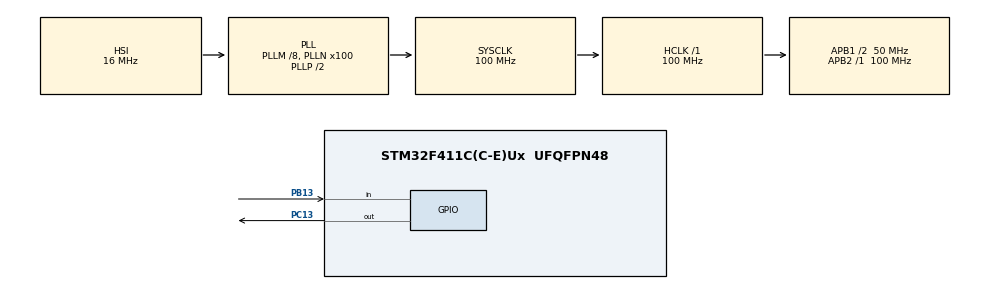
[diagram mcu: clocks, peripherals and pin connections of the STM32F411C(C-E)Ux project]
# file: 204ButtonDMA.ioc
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Dma.Request0=TIM2_CH3/UP
Dma.TIM2_CH3/UP.0.Direction=DMA_PERIPH_TO_MEMORY
Dma.TIM2_CH3/UP.0.FIFOMode=DMA_FIFOMODE_DISABLE
Dma.TIM2_CH3/UP.0.Instance=DMA1_Stream1
Dma.TIM2_CH3/UP.0.MemDataAlignment=DMA_MDATAALIGN_HALFWORD
Dma.TIM2_CH3/UP.0.MemInc=DMA_MINC_ENABLE
Dma.TIM2_CH3/UP.0.Mode=DMA_CIRCULAR
Dma.TIM2_CH3/UP.0.PeriphDataAlignment=DMA_PDATAALIGN_HALFWORD
Dma.TIM2_CH3/UP.0.PeriphInc=DMA_PINC_DISABLE
Dma.TIM2_CH3/UP.0.Priority=DMA_PRIORITY_LOW
Mcu.Family=STM32F4
Mcu.Name=STM32F411C(C-E)Ux
Mcu.Package=UFQFPN48
NVIC.DMA1_Stream1_IRQn=true\:0\:0\:false\:false\:true\:false\:true\:true
NVIC.PriorityGroup=NVIC_PRIORITYGROUP_4
PA13.Mode=Serial_Wire
PA13.Signal=SYS_JTMS-SWDIO
PA14.Mode=Serial_Wire
PA14.Signal=SYS_JTCK-SWCLK
PB13.GPIO_PuPd=GPIO_PULLUP
PB13.Signal=GPIO_Input
PC13-ANTI_TAMP.GPIO_PuPd=GPIO_NOPULL
PC13-ANTI_TAMP.Signal=GPIO_Output
ProjectManager.HeapSize=0x200
ProjectManager.StackSize=0x400
ProjectManager.TargetToolchain=STM32CubeIDE
RCC.48MHZClocksFreq_Value=50000000
RCC.AHBFreq_Value=100000000
RCC.APB1CLKDivider=RCC_HCLK_DIV2
RCC.APB1Freq_Value=50000000
RCC.APB1TimFreq_Value=100000000
RCC.APB2Freq_Value=100000000
RCC.APB2TimFreq_Value=100000000
RCC.CortexFreq_Value=100000000
RCC.HCLKFreq_Value=100000000
RCC.HSE_VALUE=25000000
RCC.HSI_VALUE=16000000
RCC.LSE_VALUE=32768
RCC.PLLM=8
RCC.PLLN=100
RCC.SYSCLKFreq_VALUE=100000000
RCC.SYSCLKSource=RCC_SYSCLKSOURCE_PLLCLK
RCC.VCOOutputFreq_Value=200000000
TIM2.Period=100-1
TIM2.Prescaler=1000-1
TIM2.TIM_MasterOutputTrigger=TIM_TRGO_UPDATE
VP_TIM2_VS_ClockSourceINT.Mode=Internal
board=custom

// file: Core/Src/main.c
/* USER CODE BEGIN Header */
/**
  ******************************************************************************
  * @file           : main.c
  * @brief          : Main program body
  ******************************************************************************
  * @attention
  *
  * Copyright (c) 2025 STMicroelectronics.
  * All rights reserved.
  *
  * This software is licensed under terms that can be found in the LICENSE file
  * in the root directory of this software component.
  * If no LICENSE file comes with this software, it is provided AS-IS.
  *
  ******************************************************************************
  */

//La Fórmula Clave
//La relación entre estos parámetros y el tiempo deseado es la siguiente:
//
//Frecuencia_Deseada = Frecuencia_Reloj_Entrada / ((Prescaler + 1) * (Counter_Period + 1))
//
//O, si quieres calcular el Tiempo_Período (el inverso de la frecuencia):
//
//Tiempo_Período = ((Prescaler + 1) * (Counter_Period + 1)) / Frecuencia_Reloj_Entrada

#include <stdio.h>
/* USER CODE END Header */
#include "main.h"

TIM_HandleTypeDef htim2;
DMA_HandleTypeDef hdma_tim2_ch3_up;

void SystemClock_Config(void);
static void MX_GPIO_Init(void);
static void MX_DMA_Init(void);
static void MX_TIM2_Init(void);

/* USER CODE BEGIN 0 */

#define SAMPLES  64
uint16_t buffer[SAMPLES]; // Guarda el estado completo de GPIOB cada 1 ms
/* USER CODE END 0 */

int main(void)
{

  /* MCU Configuration--------------------------------------------------------*/

  /* Reset of all peripherals, Initializes the Flash interface and the Systick. */
  HAL_Init();

  /* Configure the system clock */
  SystemClock_Config();

  /* Initialize all configured peripherals */
  MX_GPIO_Init();
  MX_DMA_Init();
  MX_TIM2_Init();
  /* USER CODE BEGIN 2 */

  // Iniciar el DMA: periférico=GPIOB->IDR, memoria=buffer, longitud=SAMPLES
  HAL_DMA_Start_IT(&hdma_tim2_ch3_up, (uint32_t)&GPIOB->IDR, (uint32_t)buffer, SAMPLES);

  // Habilitar request de DMA por actualización de TIM2
  __HAL_TIM_ENABLE_DMA(&htim2, TIM_DMA_ID_UPDATE);

  // Arrancar el timer
  HAL_TIM_Base_Start(&htim2);
  /* USER CODE END 2 */

  /* Infinite loop */
  while (1)
  {

  }
}

void SystemClock_Config(void)
{
  RCC_OscInitTypeDef RCC_OscInitStruct = {0};
  RCC_ClkInitTypeDef RCC_ClkInitStruct = {0};

  /** Configure the main internal regulator output voltage
  */
  __HAL_RCC_PWR_CLK_ENABLE();
  __HAL_PWR_VOLTAGESCALING_CONFIG(PWR_REGULATOR_VOLTAGE_SCALE1);

  /** Initializes the RCC Oscillators according to the specified parameters
  * in the RCC_OscInitTypeDef structure.
  */
  RCC_OscInitStruct.OscillatorType = RCC_OSCILLATORTYPE_HSI;
  RCC_OscInitStruct.HSIState = RCC_HSI_ON;
  RCC_OscInitStruct.HSICalibrationValue = RCC_HSICALIBRATION_DEFAULT;
  RCC_OscInitStruct.PLL.PLLState = RCC_PLL_ON;
  RCC_OscInitStruct.PLL.PLLSource = RCC_PLLSOURCE_HSI;
  RCC_OscInitStruct.PLL.PLLM = 8;
  RCC_OscInitStruct.PLL.PLLN = 100;
  RCC_OscInitStruct.PLL.PLLP = RCC_PLLP_DIV2;
  RCC_OscInitStruct.PLL.PLLQ = 4;
  if (HAL_RCC_OscConfig(&RCC_OscInitStruct) != HAL_OK)
  {
    Error_Handler();
  }

  /** Initializes the CPU, AHB and APB buses clocks
  */
  RCC_ClkInitStruct.ClockType = RCC_CLOCKTYPE_HCLK|RCC_CLOCKTYPE_SYSCLK
                              |RCC_CLOCKTYPE_PCLK1|RCC_CLOCKTYPE_PCLK2;
  RCC_ClkInitStruct.SYSCLKSource = RCC_SYSCLKSOURCE_PLLCLK;
  RCC_ClkInitStruct.AHBCLKDivider = RCC_SYSCLK_DIV1;
  RCC_ClkInitStruct.APB1CLKDivider = RCC_HCLK_DIV2;
  RCC_ClkInitStruct.APB2CLKDivider = RCC_HCLK_DIV1;

  if (HAL_RCC_ClockConfig(&RCC_ClkInitStruct, FLASH_LATENCY_3) != HAL_OK)
  {
    Error_Handler();
  }
}

static void MX_TIM2_Init(void)
{

  TIM_ClockConfigTypeDef sClockSourceConfig = {0};
  TIM_MasterConfigTypeDef sMasterConfig = {0};

  htim2.Instance = TIM2;
  htim2.Init.Prescaler = 1000-1;
  htim2.Init.CounterMode = TIM_COUNTERMODE_UP;
  htim2.Init.Period = 100-1;
  htim2.Init.ClockDivision = TIM_CLOCKDIVISION_DIV1;
  htim2.Init.AutoReloadPreload = TIM_AUTORELOAD_PRELOAD_DISABLE;
  if (HAL_TIM_Base_Init(&htim2) != HAL_OK)
  {
    Error_Handler();
  }
  sClockSourceConfig.ClockSource = TIM_CLOCKSOURCE_INTERNAL;
  if (HAL_TIM_ConfigClockSource(&htim2, &sClockSourceConfig) != HAL_OK)
  {
    Error_Handler();
  }
  sMasterConfig.MasterOutputTrigger = TIM_TRGO_UPDATE;
  sMasterConfig.MasterSlaveMode = TIM_MASTERSLAVEMODE_DISABLE;
  if (HAL_TIMEx_MasterConfigSynchronization(&htim2, &sMasterConfig) != HAL_OK)
  {
    Error_Handler();
  }

}

static void MX_DMA_Init(void)
{

  /* DMA controller clock enable */
  __HAL_RCC_DMA1_CLK_ENABLE();

  hdma_tim2_ch3_up.Instance = DMA1_Stream1;
  hdma_tim2_ch3_up.Init.Channel = DMA_CHANNEL_3;
  hdma_tim2_ch3_up.Init.Direction = DMA_PERIPH_TO_MEMORY;
  hdma_tim2_ch3_up.Init.PeriphInc = DMA_PINC_DISABLE;
  hdma_tim2_ch3_up.Init.MemInc = DMA_MINC_ENABLE;
  hdma_tim2_ch3_up.Init.PeriphDataAlignment = DMA_PDATAALIGN_HALFWORD;
  hdma_tim2_ch3_up.Init.MemDataAlignment = DMA_MDATAALIGN_HALFWORD;
  hdma_tim2_ch3_up.Init.Mode = DMA_NORMAL;
  hdma_tim2_ch3_up.Init.Priority = DMA_PRIORITY_HIGH;
  hdma_tim2_ch3_up.Init.FIFOMode = DMA_FIFOMODE_DISABLE;
  if (HAL_DMA_Init(&hdma_tim2_ch3_up) != HAL_OK) {
      Error_Handler();
  }

  __HAL_LINKDMA(&htim2, hdma[TIM_DMA_ID_UPDATE], hdma_tim2_ch3_up);

  /* DMA interrupt init */
  /* DMA1_Stream1_IRQn interrupt configuration */
  HAL_NVIC_SetPriority(DMA1_Stream1_IRQn, 0, 0);
  HAL_NVIC_EnableIRQ(DMA1_Stream1_IRQn);

}

static void MX_GPIO_Init(void)
{
  GPIO_InitTypeDef GPIO_InitStruct = {0};

  /* GPIO Ports Clock Enable */
  __HAL_RCC_GPIOC_CLK_ENABLE();
  __HAL_RCC_GPIOB_CLK_ENABLE();
  __HAL_RCC_GPIOA_CLK_ENABLE();

  /*Configure GPIO pin Output Level */
  HAL_GPIO_WritePin(GPIOC, GPIO_PIN_13, GPIO_PIN_RESET);

  /*Configure GPIO pin : PC13 */
  GPIO_InitStruct.Pin = GPIO_PIN_13;
  GPIO_InitStruct.Mode = GPIO_MODE_OUTPUT_PP;
  GPIO_InitStruct.Pull = GPIO_NOPULL;
  GPIO_InitStruct.Speed = GPIO_SPEED_FREQ_LOW;
  HAL_GPIO_Init(GPIOC, &GPIO_InitStruct);

  /*Configure GPIO pin : PB13 */
  GPIO_InitStruct.Pin = GPIO_PIN_13;
  GPIO_InitStruct.Mode = GPIO_MODE_INPUT;
  GPIO_InitStruct.Pull = GPIO_PULLUP;
  HAL_GPIO_Init(GPIOB, &GPIO_InitStruct);

}

/* USER CODE BEGIN 4 */

void HAL_DMA_ConvCpltCallback(DMA_HandleTypeDef *hdma)
{
    if (hdma->Instance == DMA1_Stream1)
    {
        // Procesa el buffer aquí: buffer[0..SAMPLES-1]
        // El bit 13 de cada muestra indica el estado de PB13 en ese instante.
        // Ejemplo:
        for (int i = 0; i < SAMPLES; ++i) {
            uint8_t pb13 = (buffer[i] & (1 << 13)) ? 1 : 0;
            // ... tu lógica de procesamiento ...
        }

        // Si quieres muestreo continuo, reinicia el DMA:
        HAL_DMA_Start_IT(hdma, (uint32_t)&GPIOB->IDR, (uint32_t)buffer, SAMPLES);
    }
}
/* USER CODE END 4 */

void Error_Handler(void)
{
  __disable_irq();
  while (1)
  {
  }
}
